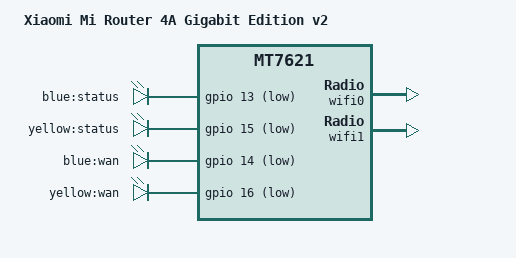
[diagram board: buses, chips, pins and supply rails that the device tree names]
// SPDX-License-Identifier: GPL-2.0-or-later OR MIT

#include "mt7621_xiaomi_mi-router-4a-common.dtsi"

/ {
	compatible = "xiaomi,mi-router-4a-gigabit-v2", "mediatek,mt7621-soc";
	model = "Xiaomi Mi Router 4A Gigabit Edition v2";

	aliases {
		label-mac-device = &wan;
	};

	leds {
		compatible = "gpio-leds";

		led_status_blue: status_blue {
			label = "blue:status";
			gpios = <&gpio 13 GPIO_ACTIVE_LOW>;
		};

		led_status_yellow: status_yellow {
			label = "yellow:status";
			gpios = <&gpio 15 GPIO_ACTIVE_LOW>;
		};

		wan_blue {
			label = "blue:wan";
			gpios = <&gpio 14 GPIO_ACTIVE_LOW>;
		};

		wan_yellow {
			label = "yellow:wan";
			gpios = <&gpio 16 GPIO_ACTIVE_LOW>;
		};
	};
};

&partitions {
	partition@180000 {
		// size changed against to the common dtsi
		reg = <0x180000 0xe70000>;
	};

	partition@ff0000 {
		label = "Config";
		reg = <0xff0000 0x10000>;
		read-only;
	};
};

&wifi0 {
	mediatek,mtd-eeprom = <&factory 0x0000>;
	ieee80211-freq-limit = <2400000 2500000>;
};

&wifi1 {
	mediatek,mtd-eeprom = <&factory 0x8000>;
	ieee80211-freq-limit = <5000000 6000000>;
};

&switch0 {
	ports {
		port@1 {
			status = "okay";
			label = "lan1";
		};

		port@2 {
			status = "okay";
			label = "lan2";
		};

		wan: port@3 {
			status = "okay";
			label = "wan";
			nvmem-cells = <&macaddr_factory_e006>;
			nvmem-cell-names = "mac-address";
		};
	};
};
